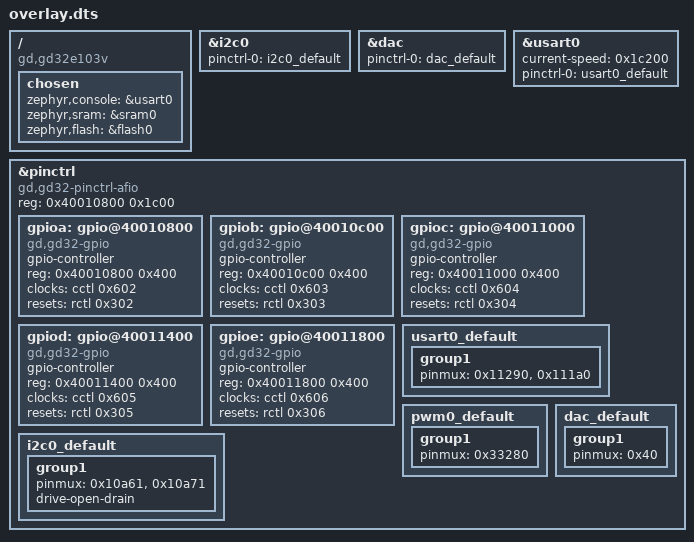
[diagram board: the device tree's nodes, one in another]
/ {
	compatible = "gd,gd32e103v";
	chosen {
		zephyr,console = &usart0;
		zephyr,sram = &sram0;
		zephyr,flash = &flash0;
	};
};
&i2c0{
	status = "okay";
	pinctrl-0 = < &i2c0_default >;
	pinctrl-names = "default";
};
&gpiob{
	status = "okay";
};
&gpiod{
	status = "okay";
};
&dac{
	status = "okay";
	pinctrl-0 = < &dac_default >;
	pinctrl-names = "default";
};
&gpioa{
	status = "okay";
};
&gpioc{
	status = "okay";
};
&gpioe{
	status = "okay";
};
&usart0{
	status = "okay";
	current-speed = < 0x1c200 >;
	pinctrl-0 = < &usart0_default >;
	pinctrl-names = "default";
};
&pinctrl{
	compatible = "gd,gd32-pinctrl-afio";
	reg = < 0x40010800 0x1c00 >;
	#address-cells = < 0x1 >;
	#size-cells = < 0x1 >;
	status = "okay";
	gpioa: gpio@40010800 {
		compatible = "gd,gd32-gpio";
		gpio-controller;
		#gpio-cells = < 0x2 >;
		reg = < 0x40010800 0x400 >;
		clocks = < &cctl 0x602 >;
		resets = < &rctl 0x302 >;
		status = "okay";
	};
	gpiob: gpio@40010c00 {
		compatible = "gd,gd32-gpio";
		gpio-controller;
		#gpio-cells = < 0x2 >;
		reg = < 0x40010c00 0x400 >;
		clocks = < &cctl 0x603 >;
		resets = < &rctl 0x303 >;
		status = "okay";
	};
	gpioc: gpio@40011000 {
		compatible = "gd,gd32-gpio";
		gpio-controller;
		#gpio-cells = < 0x2 >;
		reg = < 0x40011000 0x400 >;
		clocks = < &cctl 0x604 >;
		resets = < &rctl 0x304 >;
		status = "okay";
	};
	gpiod: gpio@40011400 {
		compatible = "gd,gd32-gpio";
		gpio-controller;
		#gpio-cells = < 0x2 >;
		reg = < 0x40011400 0x400 >;
		clocks = < &cctl 0x605 >;
		resets = < &rctl 0x305 >;
		status = "okay";
	};
	gpioe: gpio@40011800 {
		compatible = "gd,gd32-gpio";
		gpio-controller;
		#gpio-cells = < 0x2 >;
		reg = < 0x40011800 0x400 >;
		clocks = < &cctl 0x606 >;
		resets = < &rctl 0x306 >;
		status = "okay";
	};
	usart0_default: usart0_default {
		group1 {
			pinmux = < 0x11290 >, < 0x111a0 >;
		};
	};
	pwm0_default: pwm0_default {
		group1 {
			pinmux = < 0x33280 >;
		};
	};
	dac_default: dac_default {
		group1 {
			pinmux = < 0x40 >;
		};
	};
	i2c0_default: i2c0_default {
		group1 {
			pinmux = < 0x10a61 >, < 0x10a71 >;
			drive-open-drain;
		};
	};
};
